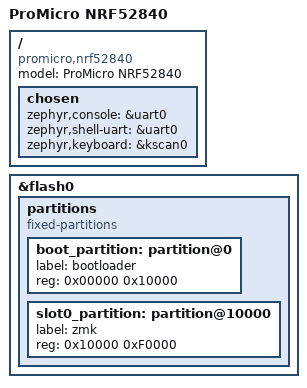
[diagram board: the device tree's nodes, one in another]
#include <nordic/nrf52840_qiaa.dtsi>

/ {
    model = "ProMicro NRF52840";
    compatible = "promicro,nrf52840";

    chosen {
        zephyr,console = &uart0;
        zephyr,shell-uart = &uart0;
        zephyr,keyboard = &kscan0;
    };
};

/* Bootloader occupies 0x00000 → 0x10000 */
&flash0 {
    partitions {
        compatible = "fixed-partitions";
        #address-cells = <1>;
        #size-cells = <1>;

        boot_partition: partition@0 {
            label = "bootloader";
            reg = <0x00000 0x10000>;
        };

        slot0_partition: partition@10000 {
            label = "zmk";
            reg = <0x10000 0xF0000>;
        };
    };
};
